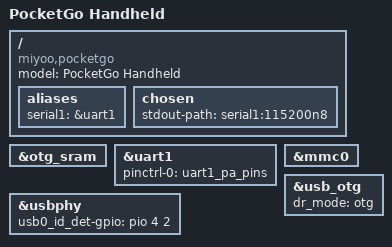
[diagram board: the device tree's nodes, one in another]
// SPDX-License-Identifier: (GPL-2.0+ OR X11)
/*
 * Copyright 2018 Icenowy Zheng <icenowy@aosc.io>
 * Copyright 2021 Yifan Gu <me@yifangu.com>
 */

/dts-v1/;
#include "suniv-f1c100s.dtsi"

#include <dt-bindings/gpio/gpio.h>

/ {
	model = "PocketGo Handheld";
	compatible = "miyoo,pocketgo", "allwinner,suniv-f1c100s",
		     "allwinner,suniv";

	aliases {
		serial1 = &uart1;
	};

	chosen {
		stdout-path = "serial1:115200n8";
	};
};

&otg_sram {
	status = "okay";
};

&uart1 {
	pinctrl-names = "default";
	pinctrl-0 = <&uart1_pa_pins>;
	status = "okay";
};

&mmc0 {
	status = "okay";
};

&usb_otg {
	dr_mode = "otg";
	status = "okay";
};

&usbphy {
	usb0_id_det-gpio = <&pio 4 2 GPIO_ACTIVE_HIGH>; /* PE2 */
	status = "okay";
};
